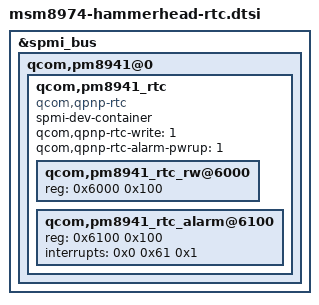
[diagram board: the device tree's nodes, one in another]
/* Copyright (c) 2012, Code Aurora Forum. All rights reserved.
 *
 * This program is free software; you can redistribute it and/or modify
 * it under the terms of the GNU General Public License version 2 and
 * only version 2 as published by the Free Software Foundation.
 *
 * This program is distributed in the hope that it will be useful,
 * but WITHOUT ANY WARRANTY; without even the implied warranty of
 * MERCHANTABILITY or FITNESS FOR A PARTICULAR PURPOSE.  See the
 * GNU General Public License for more details.
 */

&spmi_bus {

	qcom,pm8941@0 {

		qcom,pm8941_rtc{
				spmi-dev-container;
				compatible = "qcom,qpnp-rtc";
				#address-cells = <1>;
				#size-cells = <1>;
				qcom,qpnp-rtc-write = <1>;
				qcom,qpnp-rtc-alarm-pwrup = <1>;
	
				qcom,pm8941_rtc_rw@6000 {
					reg = <0x6000 0x100>;
				};
				qcom,pm8941_rtc_alarm@6100 {
					reg = <0x6100 0x100>;
					interrupts = <0x0 0x61 0x1>; 
				};
		};
	};
};

